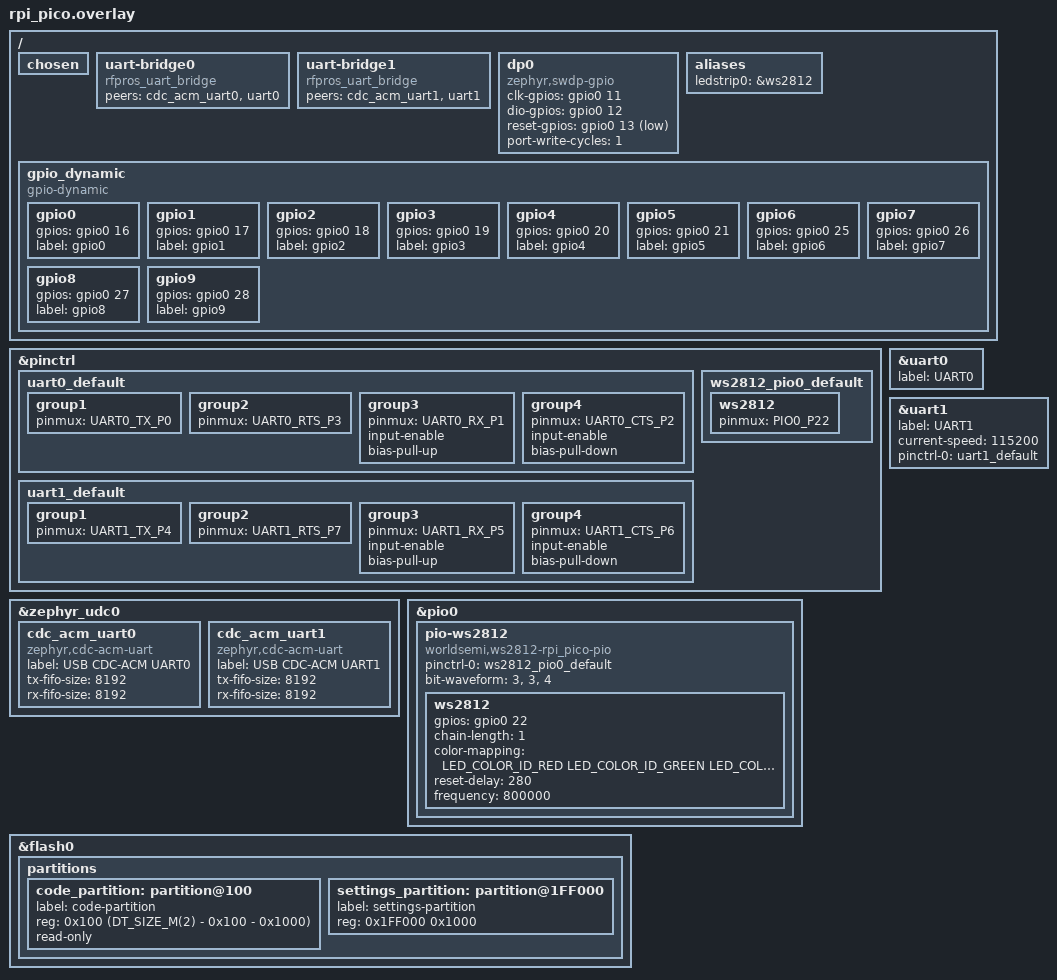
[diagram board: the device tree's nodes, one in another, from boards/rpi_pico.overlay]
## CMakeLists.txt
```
# SPDX-License-Identifier: LicenseRef-Ezurio-Clause

cmake_minimum_required(VERSION 3.20.0)

if(CONFIG_APP_DEBUG)
  set(EXTRA_CONF_FILE ${CMAKE_CURRENT_LIST_DIR}/debug.conf)
  set(EXTRA_DTC_OVERLAY_FILE ${CMAKE_CURRENT_LIST_DIR}/debug.overlay)
endif()

find_package(Zephyr REQUIRED HINTS)

project(dvk_probe)

zephyr_include_directories(include)
FILE(GLOB app_sources src/*.c)
target_sources(app PRIVATE ${app_sources})
```

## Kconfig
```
# Copyright 2025 Google LLC
# Copyright 2025 Ezurio
# SPDX-License-Identifier: LicenseRef-Ezurio-Clause

menu "DVK Probe options"
	depends on USB_DEVICE_STACK_NEXT
	depends on UART_INTERRUPT_DRIVEN
	depends on RING_BUFFER

module=DVK_PROBE
module-dep=LOG
module-str=Log level
source "${ZEPHYR_BASE}/subsys/logging/Kconfig.template.log_config"

config APP_USBD_MANUFACTURER
	string "USB device manufacturer string"
	default "Ezurio"
	help
	  USB device manufacturer string.

config APP_USBD_PRODUCT
	string "USB device product string"
	default "DVK Probe"
	help
	  USB device product string.

config APP_USBD_VID
	hex "USB device Vendor ID"
	default 0x3016
	help
	  USB device Vendor ID.

config APP_USBD_PID
	hex "USB device Product ID"
	default 0x0008
	help
	  USB device Product ID.

config APP_USBD_SELF_POWERED
	bool "USB device Self-powered attribute"
	help
	  Set the Self-powered attribute in the configuration.

config APP_USBD_REMOTE_WAKEUP
	bool "USB device Remote Wakeup attribute"
	help
	  Set the Remote Wakeup attribute in the configuration.

config APP_USBD_MAX_POWER
	int "USB device bMaxPower value"
	default 250
	range 0 250
	help
	  bMaxPower value in the configuration in 2 mA units.

config APP_USBD_20_EXTENSION_DESC
	bool "Use default USB 2.0 Extension Descriptor"
	default y
	depends on USBD_BOS_SUPPORT
	help
	  Set bcdUSB value to 0201 and use default USB 2.0 Extension Descriptor.

config APP_DEBUG
	bool "Enable debug logs"
	help
	  Enable debug logs for DVK Probe application.
	  This will add a USB CDC ACM port for debug logs.

config RFPROS_UART_BRIDGE_BUF_SIZE
	int "UART bridge buffer size"
	default 256
	help
	  Set the buffer size for the UART bridge.

endmenu

source "Kconfig.zephyr"
```

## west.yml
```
manifest:
  remotes:
    - name: zephyr
      url-base: https://github.com/zephyrproject-rtos/
    - name: rfpros
      url-base: https://github.com/rfpros

  defaults:
    remote: rfpros
    revision: main

  projects:
    - name: utp_python_common_lib
      revision: 3ceca9d6c383bc7f93e47808a18a3fa6aca86825
    - name: zephyr
      revision: 84c8e9c5e381e6b7518472a7183dcbc953458c22
      import:
        name-allowlist:
          - cmsis
          - cmsis_6
          - hal_rpi_pico
          - picolibc

  self:
    path: dvk_probe
```

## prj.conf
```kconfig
CONFIG_UART_CONSOLE=n

CONFIG_USB_DEVICE_STACK_NEXT=y
CONFIG_UDC_BUF_POOL_SIZE=16384
CONFIG_RFPROS_UART_BRIDGE_BUF_SIZE=8192

# Enable dedicated CDC ACM workqueue for better responsiveness
CONFIG_USBD_MAX_UDC_MSG=32
CONFIG_USBD_MSG_DEFERRED_MODE=n
CONFIG_USBD_CDC_ACM_WORKQUEUE=y
CONFIG_USBD_CDC_ACM_STACK_SIZE=2048

CONFIG_SERIAL=y
CONFIG_UART_LINE_CTRL=y
CONFIG_UART_USE_RUNTIME_CONFIGURE=y
CONFIG_USBD_CDC_ACM_CLASS=y
CONFIG_CDC_ACM_SERIAL_INITIALIZE_AT_BOOT=n

CONFIG_DAP=y
CONFIG_DAP_BACKEND_USB=y
CONFIG_DAP_BACKEND_USB_MAX_PACKET_SIZE=512
CONFIG_GPIO=y
CONFIG_CMSIS_DAP_PROBE_VENDOR="Ezurio"
CONFIG_CMSIS_DAP_PROBE_NAME="DVK Probe CMSIS-DAP"
CONFIG_CMSIS_DAP_BOARD_VENDOR="Ezurio"
CONFIG_CMSIS_DAP_BOARD_NAME="DVK"
CONFIG_CMSIS_DAP_DEVICE_VENDOR="Arm"
CONFIG_CMSIS_DAP_DEVICE_NAME="cortex_m"

CONFIG_LED_STRIP=y
CONFIG_WS2812_STRIP_RPI_PICO_PIO=y
CONFIG_ZBUS=y

# Flash and storage support
CONFIG_FLASH=y
CONFIG_FLASH_MAP=y
CONFIG_FLASH_PAGE_LAYOUT=y

# Reboot support
CONFIG_REBOOT=y
```

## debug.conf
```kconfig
CONFIG_LOG=y
CONFIG_UART_CONSOLE=y
CONFIG_LOG_BUFFER_SIZE=10240
CONFIG_LOG_PROCESS_THREAD_STARTUP_DELAY_MS=5000
CONFIG_LOG_PROCESS_THREAD_SLEEP_MS=15

CONFIG_SHELL=y

CONFIG_USBD_CDC_ACM_LOG_LEVEL_OFF=y
# CONFIG_UART_LOG_LEVEL_DBG=y
CONFIG_DAP_LOG_LEVEL_INF=y
CONFIG_USBD_LOG_LEVEL_WRN=y
CONFIG_DP_DRIVER_LOG_LEVEL_INF=y
```

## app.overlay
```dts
/*
 * Copyright 2025 Google LLC
 *
 * SPDX-License-Identifier: Apache-2.0
 */

/ {
	uart-bridge0 {
		compatible = "zephyr,uart-bridge";
		peers = <&cdc_acm_uart0 &uart0>;
	};
};

&zephyr_udc0 {
	cdc_acm_uart0: cdc_acm_uart0 {
		compatible = "zephyr,cdc-acm-uart";
		label = "Zephyr USB CDC-ACM";
	};
};
```

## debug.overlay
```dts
/ {
	chosen {
		// For debug console over USB CDC-ACM
		zephyr,console = &cdc_acm_uart2;
		zephyr,shell-uart = &cdc_acm_uart2;
	};
};

&zephyr_udc0 {
	cdc_acm_uart2: cdc_acm_uart2 {
		compatible = "zephyr,cdc-acm-uart";
		label = "DVK Probe DEBUG";
	};
};
```

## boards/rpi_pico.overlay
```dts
#include <dt-bindings/led/led.h>

/ {
	chosen {
		/delete-property/ zephyr,console;
		/delete-property/ zephyr,shell-uart;
	};

	uart-bridge0 {
		compatible = "rfpros_uart_bridge";
		peers = <&cdc_acm_uart0 &uart0>;
	};

	uart-bridge1 {
		compatible = "rfpros_uart_bridge";
		peers = <&cdc_acm_uart1 &uart1>;
	};

	dp0 {
		compatible = "zephyr,swdp-gpio";
		status = "okay";
		clk-gpios = <&gpio0 11 GPIO_ACTIVE_HIGH>;
		dio-gpios = <&gpio0 12 GPIO_PULL_UP>;
		reset-gpios = <&gpio0 13 (GPIO_ACTIVE_LOW | GPIO_PULL_UP)>;
		port-write-cycles = <1>;
	};

	aliases {
		ledstrip0 = &ws2812;
	};

	gpio_dynamic {
		compatible = "gpio-dynamic";
		gpio0 {
		   gpios = <&gpio0 16 0>;
		   label = "gpio0";
		};
		gpio1 {
		   gpios = <&gpio0 17 0>;
		   label = "gpio1";
		};
		gpio2 {
		   gpios = <&gpio0 18 0>;
		   label = "gpio2";
		};
		gpio3 {
		   gpios = <&gpio0 19 0>;
		   label = "gpio3";
		};
		gpio4 {
		   gpios = <&gpio0 20 0>;
		   label = "gpio4";
		};
		gpio5 {
		   gpios = <&gpio0 21 0>;
		   label = "gpio5";
		};
		gpio6 {
		   gpios = <&gpio0 25 0>;
		   label = "gpio6";
		};
		gpio7 {
		   gpios = <&gpio0 26 0>;
		   label = "gpio7";
		};
		gpio8 {
		   gpios = <&gpio0 27 0>;
		   label = "gpio8";
		};
		gpio9 {
		   gpios = <&gpio0 28 0>;
		   label = "gpio9";
		};
	 };
};

&pinctrl {
	uart0_default: uart0_default {
		group1 {
			pinmux = <UART0_TX_P0>;
		};
		group2 {
			pinmux = <UART0_RTS_P3>;
		};
		group3 {
			pinmux = <UART0_RX_P1>;
			input-enable;
			bias-pull-up;
		};
		group4 {
			pinmux = <UART0_CTS_P2>;
			input-enable;
			bias-pull-down;
		};
	};

	uart1_default: uart1_default {
		group1 {
			pinmux = <UART1_TX_P4>;
		};
		group2 {
			pinmux = <UART1_RTS_P7>;
		};
		group3 {
			pinmux = <UART1_RX_P5>;
			input-enable;
			bias-pull-up;
		};
		group4 {
			pinmux = <UART1_CTS_P6>;
			input-enable;
			bias-pull-down;
		};
	};

	ws2812_pio0_default: ws2812_pio0_default {
		ws2812 {
			pinmux = <PIO0_P22>;
		};
	};
};

&uart0 {
	label = "UART0";
};

&uart1 {
	label = "UART1";
	current-speed = <115200>;
	status = "okay";
	pinctrl-0 = <&uart1_default>;
	pinctrl-names = "default";
};

&zephyr_udc0 {
	cdc_acm_uart0: cdc_acm_uart0 {
		compatible = "zephyr,cdc-acm-uart";
		label = "USB CDC-ACM UART0";
		tx-fifo-size = <8192>;
		rx-fifo-size = <8192>;
	};

	cdc_acm_uart1: cdc_acm_uart1 {
		compatible = "zephyr,cdc-acm-uart";
		label = "USB CDC-ACM UART1";
		tx-fifo-size = <8192>;
		rx-fifo-size = <8192>;
	};
};

&pio0 {
	status = "okay";

	pio-ws2812 {
		compatible = "worldsemi,ws2812-rpi_pico-pio";
		status = "okay";
		pinctrl-0 = <&ws2812_pio0_default>;
		pinctrl-names = "default";
		bit-waveform = <3>, <3>, <4>;

		ws2812: ws2812 {
			status = "okay";
			gpios = <&gpio0 22 GPIO_ACTIVE_HIGH>;
			chain-length = <1>;
			color-mapping = <LED_COLOR_ID_RED
				LED_COLOR_ID_GREEN
				LED_COLOR_ID_BLUE>;
			reset-delay = <280>;
			frequency = <800000>;
		};
	};
};

&flash0 {
	partitions {
		/*
		 * Usable flash. Starts at 0x100, after the bootloader. The partition
		 * size is 2MB minus the 0x100 bytes taken by the bootloader and the settings area.
		 */
		code_partition: partition@100 {
			label = "code-partition";
			reg = <0x100 (DT_SIZE_M(2) - 0x100 - 0x1000)>;
			read-only;
		};

		settings_partition: partition@1FF000 {
			label = "settings-partition";
			reg = <0x1FF000 0x1000>;
		};
	};
};
```

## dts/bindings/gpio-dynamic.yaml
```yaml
# Copyright (c) 2018, Linaro Limited
# Copyright (c) 2023-2024, Laird Connectivity
#
# SPDX-License-Identifier: Apache-2.0

description: |
  This allows you to define a group of GPIO that are configurable at run-time.
  Each pin is defined in a child node of the gpio-dynamic node.

  This example defines three children in the node /gpio_dynamic.

  The GPIO flags are ignored by the pi_dapi_gpio driver because they are
  set from the [Python] application.

  / {
     gpio_dynamic {
        compatible = "gpio-dynamic";
        test_point_0 {
           gpios = <&gpio0 1 0>;
           label = "TEST_POINT_0,TP0";
        };
        test_point_1 {
           gpios = <&gpio0 2 0>;
           label = "TEST_POINT_1";
        };
        test_point_2 {
           gpios = <&gpio1 15 0>;
        };
     };
  };

compatible: "gpio-dynamic"

child-binding:
    description: Dynamic GPIO child node
    properties:
       gpios:
          type: phandle-array
          required: true
       label:
          type: string
          description: |
            Human readable string describing the gpio. It can be used by an
            application/script to identify this test point or to retrieve 
            its number/index (i.e. child node number) on the parent device.
            Multiple names can be specified as a comma separated list.
```

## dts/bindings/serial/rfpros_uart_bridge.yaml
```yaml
# Copyright 2025 Google LLC
# Copyright 2025 Ezurio
# SPDX-License-Identifier: LicenseRef-Ezurio-Clause

title: UART bridge

description: |
  Bridges data between two serial devices, for example a USB CDC-ACM serial
  port and an hardware UART.

  The device node must specify exactly two peer phandles for the two serial
  devices to be bridged together. Example configuration:

  uart-bridge {
           compatible = "rfpros_uart_bridge";
           peers = <&cdc_acm_uart0 &uart1>;
  };

include: base.yaml

compatible: "rfpros_uart_bridge"

properties:
  peers:
    type: phandles
    description: Peer device nodes, must contain two phandles
```

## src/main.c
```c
/*
 * Copyright 2025 Google LLC
 * Copyright 2025 Ezurio
 *
 * SPDX-License-Identifier: LicenseRef-Ezurio-Clause
 */

#include <stdio.h>
#include <string.h>
#include <zephyr/kernel.h>
#include <zephyr/drivers/gpio.h>
#include <zephyr/drivers/uart.h>
#include <zephyr/usb/usb_device.h>
#include <zephyr/usb/usbd.h>
#include <zephyr/app_version.h>
#include <cmsis_dap.h>

#include <zephyr/logging/log.h>
LOG_MODULE_REGISTER(dvk_probe, CONFIG_DVK_PROBE_LOG_LEVEL);

#include "uart_bridge.h"
#include "app_usbd.h"
#include "led.h"
#include "probe_settings.h"
#include "dap_vendor.h"

#define TARGET_RESET_PULSE_MS 50

static struct usbd_context *app_usbd;

#define DEVICE_DT_GET_COMMA(node_id) DEVICE_DT_GET(node_id),

static const struct device *const swd_dev = DEVICE_DT_GET_ONE(zephyr_swdp_gpio);

static const struct device *uart_bridges[] = {
	DT_FOREACH_STATUS_OKAY(rfpros_uart_bridge, DEVICE_DT_GET_COMMA)};

/* Get the node ID of gpio_dynamic */
#define GPIO_DYNAMIC_NODE DT_PATH(gpio_dynamic)

/* Macro to extract gpio_dt_spec from a child node */
#define GPIO_SPEC_FROM_CHILD(child_node) GPIO_DT_SPEC_GET_BY_IDX(child_node, gpios, 0),

/* Get all dynamic GPIOs */
static const struct gpio_dt_spec gpios[] = {
	DT_FOREACH_CHILD(GPIO_DYNAMIC_NODE, GPIO_SPEC_FROM_CHILD)};

/* Target reset GPIO */
#define SWDP_NODE DT_COMPAT_GET_ANY_STATUS_OKAY(zephyr_swdp_gpio)
static const struct gpio_dt_spec target_reset_gpio =
	GPIO_DT_SPEC_GET(SWDP_NODE, reset_gpios);

ZBUS_CHAN_DECLARE(led_chan);
ZBUS_SUBSCRIBER_DEFINE(led_sub, 8);

static void usbd_msg_cb(struct usbd_context *const ctx, const struct usbd_msg *msg)
{
	uint32_t line_ctrl_status;
	uint8_t dev_idx;
	const struct device *uart_dev = NULL;
	int ret;
	struct uart_config peer_cfg;

	LOG_DBG("USBD message: %s", usbd_msg_type_string(msg->type));

	if (usbd_can_detect_vbus(ctx)) {
		if (msg->type == USBD_MSG_VBUS_READY) {
			if (usbd_enable(ctx)) {
				LOG_ERR("Failed to enable device support");
			}
		}

		if (msg->type == USBD_MSG_VBUS_REMOVED) {
			if (usbd_disable(ctx)) {
				LOG_ERR("Failed to disable device support");
			}
		}
	}

	if (msg->type == USBD_MSG_CDC_ACM_LINE_CODING ||
	    msg->type == USBD_MSG_CDC_ACM_CONTROL_LINE_STATE) {
		for (dev_idx = 0; dev_idx < ARRAY_SIZE(uart_bridges); dev_idx++) {
			/* Find the matching device */
			uart_dev = uart_bridge_get_peer(msg->dev, uart_bridges[dev_idx]);
			if (uart_dev != NULL) {
				break;
			}
		}

		if (uart_dev == NULL) {
			LOG_DBG("No matching UART bridge for %s", msg->dev->name);
			return;
		}

		/* Get the current UART configuration of the USB CDC ACM device */
		ret = uart_config_get(msg->dev, &peer_cfg);
		if (ret != 0) {
			LOG_ERR("Failed to get UART config: %d", ret);
			return;
		}

		/* Check if the USB CDC ACM device is ready for operation */
		ret = uart_line_ctrl_get(msg->dev, UART_LINE_CTRL_DTR, &line_ctrl_status);
		if (ret == 0) {
			if (line_ctrl_status) {
				LOG_INF("DTR set: enable UART bridge %s", uart_dev->name);
				uart_bridge_settings_update(msg->dev, uart_bridges[dev_idx]);
				peer_cfg.flow_ctrl = UART_CFG_FLOW_CTRL_RTS_CTS;
			} else {
				LOG_INF("DTR cleared: disable UART bridge %s", uart_dev->name);
				/* This sets RTS back high when the USB UART is closed */
				peer_cfg.flow_ctrl = UART_CFG_FLOW_CTRL_NONE;
			}

			ret = uart_configure(uart_dev, &peer_cfg);
			if (ret) {
				LOG_ERR("%s: failed to set the uart config: %d", uart_dev->name,
					ret);
				return;
			}
		} else {
			LOG_ERR("Failed to get DTR status: %d", ret);
		}
	}
}

int main(void)
{
	int err;
	led_action_t led_boot_action = {
		.dev = led_strip,
		.color = LED_COLOR_WHITE,
		.on_time_ms = LED_FLASH_TIME_MS,
		.off_time_ms = LED_FLASH_TIME_MS,
		.repeat_count = 2,
	};
	led_action_t msg_led_action;
	const struct zbus_channel *chan;

	for (size_t i = 0; i < ARRAY_SIZE(gpios); i++) {
		if (gpio_pin_configure_dt(&gpios[i], GPIO_DISCONNECTED) != 0) {
			LOG_ERR("Could not configure GPIO %s", gpios[i].port->name);
		}
	}

	if (led_init() != 0) {
		LOG_ERR("LED strip device %s is not ready", led_strip->name);
		return -ENODEV;
	}

	err = dap_setup(swd_dev);
	if (err) {
		LOG_ERR("Failed to initialize DAP controller, %d", err);
		return err;
	}

	dap_set_fw_version(APP_VERSION_STRING);

	err = dap_set_vendor_cmd_callback(dap_vendor_cmd_handler);
	if (err < 0) {
		LOG_ERR("Failed to register vendor command callback: %d", err);
	}

	/* Initialize probe settings */
	probe_settings_init();

	/* Set DAP device info from probe settings */
	if (probe_settings != NULL && probe_settings->base.version >= PROBE_SETTINGS_V1) {
		err = dap_set_device_info(probe_settings->v1.target_device_vendor,
					  probe_settings->v1.target_device_name,
					  probe_settings->v1.target_board_vendor,
					  probe_settings->v1.target_board_name);
		if (err) {
			LOG_WRN("Failed to set DAP device info: %d", err);
		} else {
			LOG_INF("DAP device info set from probe settings");
		}
	}

	app_usbd = app_usbd_setup_device(usbd_msg_cb);
	if (app_usbd == NULL) {
		LOG_ERR("Failed to setup USB device");
		return -ENODEV;
	}

	/* Set USB VID and PID from probe settings */
	if (probe_settings != NULL && probe_settings->base.version >= PROBE_SETTINGS_V2) {
		err = usbd_device_set_vid(app_usbd, probe_settings->v2.usb_vid);
		if (err) {
			LOG_WRN("Failed to set USB VID: %d", err);
		}
		err = usbd_device_set_pid(app_usbd, probe_settings->v2.usb_pid);
		if (err) {
			LOG_WRN("Failed to set USB PID: %d", err);
		}
		LOG_INF("USB VID:PID set to 0x%04x:0x%04x", probe_settings->v2.usb_vid,
			probe_settings->v2.usb_pid);
	}

	/* Reset target device on boot */
	if (!gpio_is_ready_dt(&target_reset_gpio)) {
		LOG_ERR("Target reset GPIO is not ready");
	} else {
		err = gpio_pin_configure_dt(&target_reset_gpio, GPIO_OUTPUT_ACTIVE);
		if (err) {
			LOG_ERR("Failed to configure target reset GPIO: %d", err);
		} else {
			LOG_DBG("Asserting target reset");
			k_msleep(TARGET_RESET_PULSE_MS);
			gpio_pin_set_dt(&target_reset_gpio, 0);
			LOG_DBG("Released target reset");
			/* Set back to disconnected so DAP can control it */
			gpio_pin_configure_dt(&target_reset_gpio, GPIO_DISCONNECTED);
		}
	}

	/* Initialize USB device */
	err = usbd_init(app_usbd);
	if (err) {
		LOG_ERR("Failed to initialize USB device: %d", err);
		return err;
	}

	if (!usbd_can_detect_vbus(app_usbd)) {
		err = usbd_enable(app_usbd);
		if (err) {
			LOG_ERR("Failed to enable device support");
			return err;
		}
	}

	LOG_INF("USB device support enabled");

	/* Flash LED to indicate boot */
	led_send_action(&led_boot_action);

	/* Main loop to process LED actions */
	while (1) {
		err = zbus_sub_wait(&led_sub, &chan, K_FOREVER);
		if (err) {
			LOG_ERR("Failed to wait for LED action: %d", err);
			k_yield();
			continue;
		}
		if (chan != &led_chan) {
			k_yield();
			continue;
		}
		err = zbus_chan_read(&led_chan, &msg_led_action, K_FOREVER);
		if (err == 0) {
			led_do_action(&msg_led_action);
		}
		k_sleep(K_MSEC(1));
		k_yield();
	}
	return 0;
}
```

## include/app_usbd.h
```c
/*
 * Copyright (c) 2023 Nordic Semiconductor ASA.
 * Copyright 2025 Ezurio
 *
 * SPDX-License-Identifier: LicenseRef-Ezurio-Clause
 */

#ifndef APP_USBD_H
#define APP_USBD_H

#include <stdint.h>
#include <zephyr/usb/usbd.h>

/*
 * This function configures and initializes a
 * USB device. It configures the device context, default string descriptors,
 * USB device configuration, registers any available class instances, and
 * finally initializes USB device.
 *
 * It returns the configured and initialized USB device context on success,
 * otherwise it returns NULL.
 */
struct usbd_context *app_usbd_init_device(usbd_msg_cb_t msg_cb);

/*
 * This function is similar to app_usbd_init_device(), but does not
 * initialize the device. It allows the application to set additional features,
 * such as additional descriptors.
 */
struct usbd_context *app_usbd_setup_device(usbd_msg_cb_t msg_cb);

#endif /* APP_USBD_H */
```

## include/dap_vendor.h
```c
/**
 * @file dap_vendor.h
 *
 * Copyright (c) 2026 Ezurio
 *
 * SPDX-License-Identifier: LicenseRef-Ezurio-Clause
 */

#ifndef __DAP_VENDOR_H__
#define __DAP_VENDOR_H__

/**************************************************************************************************/
/* Includes                                                                                       */
/**************************************************************************************************/
#include <cmsis_dap.h>

#ifdef __cplusplus
extern "C" {
#endif

/**************************************************************************************************/
/* Global Constants, Macros and Type Definitions                                                  */
/**************************************************************************************************/

/* clang-format off */
/**
 * @brief Set IO to input or output
 * @param uint8_t gpio to set
 * @param uint8_t direction 1 = output, 0 = input
 * @param uint8_t option 0 = no-pull, 1 = pull-up, 2 = pull-down, 3 = disconnect
 */
#define ID_DAP_VENDOR_SET_IO_DIR        ID_DAP_VENDOR31
/**
 * @brief Set IO to high or low
 * @param uint8_t gpio to set
 * @param uint8_t level 1 = high, 0 = low
 */
#define ID_DAP_VENDOR_SET_IO            (ID_DAP_VENDOR31 - 1)
/**
 * @brief Read IO state
 * @param uint8_t gpio to read
 * @return uint8_t < 0 error, 1 = high, 0 = low
 */
#define ID_DAP_VENDOR_READ_IO           (ID_DAP_VENDOR31 - 2)

/**
 * @brief Deprecated EEPROM read/write functions. Use read/write settings instead.
 * These defines are here for informational purposes only.
 */
#define ID_DAP_VENDOR_READ_BOARD_ID_BYTES   (ID_DAP_VENDOR31 - 3)
#define ID_DAP_VENDOR_WRITE_BOARD_ID_BYTES  (ID_DAP_VENDOR31 - 4)

/**
 * @brief Reboot the debug probe
 * @param uint8_t reboot to bootloader if 1, else reboot and run application
 */
#define ID_DAP_VENDOR_REBOOT                (ID_DAP_VENDOR31 - 5)

/**
 * @brief Read settings from probe (internal flash)
 * @return bytes read. length of bytes read is always 256 bytes. < 0 indicates error
 */
#define ID_DAP_VENDOR_READ_SETTINGS         (ID_DAP_VENDOR31 - 6)

/**
 * @brief Write settings to probe (internal flash)
 * @param uint8_t number of bytes to write (max 256)
 * @param uint8_t* bytes to write. This will always be 256 bytes (a full settings page)
 * @return int8_t result 0 on success, < 0 indicates error
 */
#define ID_DAP_VENDOR_WRITE_SETTINGS        (ID_DAP_VENDOR31 - 7)

/* clang-format on */

enum {
	DAP_VENDOR_ERR_INVALID_IO = 1,
	DAP_VENDOR_ERR_INVALID_IO_OPTION,
	DAP_VENDOR_ERR_INVALID_SIZE,
};

enum {
	IO_OPTION_NO_PULL = 0,
	IO_OPTION_PULL_UP,
	IO_OPTION_PULL_DOWN,
	IO_OPTION_DISCONNECT,
	IO_OPTION_INVALID,
};

/**************************************************************************************************/
/* Global Function Prototypes                                                                     */
/**************************************************************************************************/
uint16_t dap_vendor_cmd_handler(uint8_t cmd_id,
				      const uint8_t *request,
				      uint8_t *response);

#ifdef __cplusplus
}
#endif

#endif /* __DAP_VENDOR_H__ */
```

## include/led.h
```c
/*
 * Copyright 2025 Ezurio
 *
 * SPDX-License-Identifier: LicenseRef-Ezurio-Clause
 */

#ifndef APP_LED_H
#define APP_LED_H

#include <zephyr/device.h>
#include <zephyr/drivers/led_strip.h>
#include <zephyr/zbus/zbus.h>

#if DT_NODE_HAS_PROP(DT_ALIAS(ledstrip0), chain_length)
#define LED_STRIP_NUM_PIXELS DT_PROP(DT_ALIAS(ledstrip0), chain_length)
#else
#error Unable to determine length of LED strip
#endif

#define LED_LEVEL_LIMIT 0.25 /* Limit max brightness to 25% to protect eyes */

#define LED_RGB(_r, _g, _b)                                                                        \
	{.r = ((uint8_t)((_r) * LED_LEVEL_LIMIT)),                                                 \
	 .g = ((uint8_t)((_g) * LED_LEVEL_LIMIT)),                                                 \
	 .b = ((uint8_t)((_b) * LED_LEVEL_LIMIT))}

#define LED_COLOR_RED   LED_RGB(255, 0, 0)
#define LED_COLOR_GREEN LED_RGB(0, 255, 0)
#define LED_COLOR_BLUE  LED_RGB(0, 0, 255)
#define LED_COLOR_WHITE  LED_RGB(255, 255, 255)
#define LED_COLOR_OFF   LED_RGB(0, 0, 0)

#define LED_FLASH_TIME_MS      30
#define LED_FLASH_FAST_TIME_MS 10

typedef struct led_action {
	const struct device *dev;
	struct led_rgb color;
	uint16_t on_time_ms;
	uint16_t off_time_ms;
	uint16_t repeat_count;
} led_action_t;

typedef enum {
	LED_BLACK, /* OFF */
	LED_RED,
	LED_GREEN,
	LED_BLUE,
	LED_WHITE,
	NUMBER_OF_LED_COLORS,
} led_color_t;

extern const struct device *const led_strip;
extern const led_action_t LED_BLUE_FLASH;
extern const led_action_t LED_RED_FLASH;
extern const led_action_t LED_GREEN_FLASH;

/**
 * @brief Send LED action to LED handler
 *
 * @param action An action to be performed on the LED. This queues the action for processing.
 *		The LED action is designed to flash LEDs and is not suitable for setting steady
 *		states.
 * @return int 0 on success, negative error code on failure
 */
int led_send_action(led_action_t *action);

/**
 * @brief Perform LED action
 *
 * @param action An action to be performed on the LED.
 *		This is a blocking call. It cannot be called from an interrupt context.
 *		The LED action is designed to flash LEDs and is not suitable for setting steady
 *		states.
 * @return int 0 on success, negative error code on failure
 */
int led_do_action(led_action_t *action);

/**
 * @brief Toggle LED color channels
 *
 * @param led_color Color channel to toggle.
 */
void toggle_led(led_color_t led_color);

/**
 * @brief Turn off specified LED color channel
 *
 * @param led_color Color channel to turn off.
 */
void led_off(led_color_t led_color);

/**
 * @brief Initialize LED subsystem
 */
int led_init(void);

#endif /* APP_LED_H */
```

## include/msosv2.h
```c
/*
 * Copyright (c) 2016-2019 Intel Corporation
 * Copyright (c) 2023-2024 Nordic Semiconductor ASA
 * Copyright 2025 Ezurio
 *
 * SPDX-License-Identifier: LicenseRef-Ezurio-Clause
 */

#ifndef APP_MSOSV2_DESCRIPTOR_H
#define APP_MSOSV2_DESCRIPTOR_H

/*
 * Microsoft OS 2.0 Descriptors for Windows 8.1+ compatibility.
 * See Microsoft OS 2.0 Descriptors Specification for reference.
 */

#define APP_MSOS_VENDOR_CODE 0x14U
/* Windows version (8.1) */
#define APP_MSOS2_OS_VERSION 0x06030000UL

/* {F9E8D7C6-B5A4-3210-DCBA-0987654321FE} */
#define CMSIS_DAP_V2_DEVICE_INTERFACE_GUID                                                         \
	'{', 0x00, 'F', 0x00, '9', 0x00, 'E', 0x00, '8', 0x00, 'D', 0x00, '7', 0x00, 'C', 0x00,    \
		'6', 0x00, '-', 0x00, 'B', 0x00, '5', 0x00, 'A', 0x00, '4', 0x00, '-', 0x00, '3',  \
		0x00, '2', 0x00, '1', 0x00, '0', 0x00, '-', 0x00, 'D', 0x00, 'C', 0x00, 'B', 0x00, \
		'A', 0x00, '-', 0x00, '0', 0x00, '9', 0x00, '8', 0x00, '7', 0x00, '6', 0x00, '5',  \
		0x00, '4', 0x00, '3', 0x00, '2', 0x00, '1', 0x00, 'F', 0x00, 'E', 0x00, '}', 0x00, \
		0x00, 0x00, 0x00, 0x00

/* CMSIS-DAP is always registered first, so it is always interface 0. */
#define DAP_INTERFACE_NUMBER   0

/*
 * The DAP function subset contains the WinUSB compatible ID and device interface GUID.
 */
#define DAP_FUNCTION_SUBSET_LENGTH                                                                 \
	(sizeof(struct msosv2_function_subset_header) + sizeof(struct msosv2_compatible_id) +      \
	 sizeof(struct msosv2_guids_property))

/*
 * Microsoft OS 2.0 Descriptor Set
 */
struct msosv2_descriptor {
	struct msosv2_descriptor_set_header header;
	/* DAP interface function subset header */
	struct msosv2_function_subset_header dap_subset_header;
	struct msosv2_compatible_id compatible_id;
	struct msosv2_guids_property guids_property;
} __packed;

const struct msosv2_descriptor msosv2_desc = {
	.header =
		{
			.wLength = sizeof(struct msosv2_descriptor_set_header),
			.wDescriptorType = MS_OS_20_SET_HEADER_DESCRIPTOR,
			.dwWindowsVersion = sys_cpu_to_le32(APP_MSOS2_OS_VERSION),
			.wTotalLength = sizeof(msosv2_desc),
		},
	/* DAP is always interface 0 */
	.dap_subset_header =
		{
			.wLength = sizeof(struct msosv2_function_subset_header),
			.wDescriptorType = MS_OS_20_SUBSET_HEADER_FUNCTION,
			.bFirstInterface = DAP_INTERFACE_NUMBER,
			.bReserved = 0,
			.wSubsetLength = DAP_FUNCTION_SUBSET_LENGTH,
		},
	.compatible_id =
		{
			.wLength = sizeof(struct msosv2_compatible_id),
			.wDescriptorType = MS_OS_20_FEATURE_COMPATIBLE_ID,
			.CompatibleID = {'W', 'I', 'N', 'U', 'S', 'B', 0x00, 0x00},
		},
	.guids_property =
		{
			.wLength = sizeof(struct msosv2_guids_property),
			.wDescriptorType = MS_OS_20_FEATURE_REG_PROPERTY,
			.wPropertyDataType = MS_OS_20_PROPERTY_DATA_REG_MULTI_SZ,
			.wPropertyNameLength = 42,
			.PropertyName = {DEVICE_INTERFACE_GUIDS_PROPERTY_NAME},
			.wPropertyDataLength = 80,
			.bPropertyData = {CMSIS_DAP_V2_DEVICE_INTERFACE_GUID},
		},
};

/*
 * Microsoft OS 2.0 Platform Capability Descriptor
 * Combined structure using Zephyr's standard BOS types
 */
struct bos_msosv2_descriptor {
	struct usb_bos_platform_descriptor platform;
	struct usb_bos_capability_msos msos;
} __packed;

const struct bos_msosv2_descriptor bos_msosv2_desc = {
	.platform =
		{
			.bLength = sizeof(struct usb_bos_platform_descriptor) +
				   sizeof(struct usb_bos_capability_msos),
			.bDescriptorType = USB_DESC_DEVICE_CAPABILITY,
			.bDevCapabilityType = USB_BOS_CAPABILITY_PLATFORM,
			.bReserved = 0,
			/* Microsoft OS 2.0 descriptor platform capability UUID
			 * D8DD60DF-4589-4CC7-9CD2-659D9E648A9F
			 */
			.PlatformCapabilityUUID =
				{
					0xDF,
					0x60,
					0xDD,
					0xD8,
					0x89,
					0x45,
					0xC7,
					0x4C,
					0x9C,
					0xD2,
					0x65,
					0x9D,
					0x9E,
					0x64,
					0x8A,
					0x9F,
				},
		},
	.msos =
		{
			.dwWindowsVersion = sys_cpu_to_le32(APP_MSOS2_OS_VERSION),
			.wMSOSDescriptorSetTotalLength = sys_cpu_to_le16(sizeof(msosv2_desc)),
			.bMS_VendorCode = APP_MSOS_VENDOR_CODE,
			.bAltEnumCode = 0x00,
		},
};

static int msos_to_host_cb(const struct usbd_context *const ctx,
			   const struct usb_setup_packet *const setup, struct net_buf *const buf)
{
	uint16_t wIndex = sys_le16_to_cpu(setup->wIndex);

	LOG_INF("MSOS Vendor callback: bRequest=0x%02x, wIndex=0x%04x", setup->bRequest, wIndex);

	/* Handle MSOS v2 requests (Windows 8.1+) */
	if (setup->bRequest == APP_MSOS_VENDOR_CODE && wIndex == MS_OS_20_DESCRIPTOR_INDEX) {
		LOG_INF("Get MS OS 2.0 Descriptor Set (len=%u)", sizeof(msosv2_desc));
		net_buf_add_mem(buf, &msosv2_desc, MIN(net_buf_tailroom(buf), sizeof(msosv2_desc)));
		return 0;
	}

	LOG_WRN("Unsupported MSOS vendor request");
	return -ENOTSUP;
}

/* Register MSOS v2 BOS descriptor with vendor request callback */
USBD_DESC_BOS_VREQ_DEFINE(bos_vreq_msosv2, sizeof(bos_msosv2_desc), &bos_msosv2_desc,
			  APP_MSOS_VENDOR_CODE, msos_to_host_cb, NULL);

#endif /* APP_MSOSV2_DESCRIPTOR_H */
```

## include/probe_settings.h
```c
/**
 * @file probe_settings.h
 * @brief API for probe NV settings
 *
 * Copyright (c) 2026 Ezurio
 *
 * SPDX-License-Identifier: LicenseRef-Ezurio-Clause
 */

#ifndef __PROBE_SETTINGS_H__
#define __PROBE_SETTINGS_H__

#ifdef __cplusplus
extern "C" {
#endif

/**************************************************************************************************/
/* Global Constants, Macros and Type Definitions                                                  */
/**************************************************************************************************/
/* clang-format off */
#define PROBE_SETTINGS_MAX_SIZE 	256
#define PROBE_SETTINGS_INVALID_FF   0xFF
#define PROBE_SETTINGS_INVALID_00   0x00
#define PROBE_SETTINGS_V1       	0x01
#define PROBE_SETTINGS_V2      		0x02
/* clang-format on */

#pragma pack(1)
typedef struct {
	uint8_t version;
	uint8_t data[PROBE_SETTINGS_MAX_SIZE - 1];
} probe_settings_base_t;

typedef struct {
	uint8_t version;
	char target_device_vendor[32];
	char target_device_name[32];
	char target_board_vendor[32];
	char target_board_name[32];
} probe_settings_v1_t;

typedef struct {
	uint8_t version;
	char target_device_vendor[32];
	char target_device_name[32];
	char target_board_vendor[32];
	char target_board_name[32];
	uint16_t usb_vid;
	uint16_t usb_pid;
} probe_settings_v2_t;

typedef union {
	probe_settings_base_t base;
	probe_settings_v1_t v1;
	probe_settings_v2_t v2;
} probe_settings_ut;
#pragma pack()

enum {
	SETTINGS_ERR_INVALID_PARAM = 1,
};

/**************************************************************************************************/
/* Global Data Definitions                                                                        */
/**************************************************************************************************/
extern const probe_settings_ut *probe_settings;

/**************************************************************************************************/
/* Global Function Prototypes                                                                     */
/**************************************************************************************************/
void probe_settings_init(void);

/**
 * @brief Write settings to internal flash
 *
 * @param settings pointer to settings data
 * @param size size of settings data
 * @return int 0 on success, < 0 on failure
 */
int write_internal_settings(const probe_settings_ut *settings, uint16_t size);

#ifdef __cplusplus
}
#endif

#endif /* __PROBE_SETTINGS_H__ */
```

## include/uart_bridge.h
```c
/*
 * Copyright 2025 Google LLC
 * Copyright 2025 Ezurio
 *
 * SPDX-License-Identifier: LicenseRef-Ezurio-Clause
 */

#ifndef RFPROS_UART_BRIDGE_H
#define RFPROS_UART_BRIDGE_H

#include <zephyr/device.h>

/**
 * @brief Update the hardware port settings on a uart bridge
 *
 * If dev is part bridge_dev, then the dev uart configuration are applied to
 * the other device in the uart bridge. This allows propagating the settings
 * from a USB CDC-ACM port to a hardware UART.
 *
 * If dev is not part of bridge_dev then the function is a no-op.
 */
void uart_bridge_settings_update(const struct device *dev, const struct device *bridge_dev);

/**
 * @brief Get the peer device in a uart bridge
 *
 * @param dev The device to find the peer for
 * @param bridge_dev The uart bridge device
 * @return const struct device* The peer device, or NULL if not found
 */
const struct device *uart_bridge_get_peer(const struct device *dev,
					  const struct device *bridge_dev);

#endif /* RFPROS_UART_BRIDGE_H */
```

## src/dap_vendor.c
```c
/*
 * @file dap_vendor.c
 *
 * Copyright 2026 Ezurio
 * Copyright (c) 2023 Laird Connectivity LLC
 *
 * SPDX-License-Identifier: LicenseRef-Ezurio-Clause
 */

/**************************************************************************************************/
/* Includes                                                                                       */
/**************************************************************************************************/
#include <zephyr/kernel.h>
#include <zephyr/drivers/gpio.h>
#include <zephyr/sys/reboot.h>
#include <zephyr/logging/log.h>
#include <pico/bootrom.h>
#include <string.h>
#include "dap_vendor.h"
#include "probe_settings.h"
#include "led.h"

LOG_MODULE_REGISTER(dap_vendor, LOG_LEVEL_INF);

/**************************************************************************************************/
/* Local Constant, Macro and Type Definitions                                                     */
/**************************************************************************************************/
#define REBOOT_DELAY_MS 100

// Get the node ID of gpio_dynamic
#define GPIO_DYNAMIC_NODE DT_PATH(gpio_dynamic)

// Macro to extract gpio_dt_spec from a child node
#define GPIO_SPEC_FROM_CHILD(child_node) GPIO_DT_SPEC_GET_BY_IDX(child_node, gpios, 0),

/**************************************************************************************************/
/* Local Data Definitions                                                                         */
/**************************************************************************************************/
// Get all dynamic GPIOs
static const struct gpio_dt_spec gpios[] = {
	DT_FOREACH_CHILD(GPIO_DYNAMIC_NODE, GPIO_SPEC_FROM_CHILD)};

static struct k_work_delayable reboot_work;
static struct k_work_delayable reboot_bootloader_work;

/**************************************************************************************************/
/* Local Function Definitions                                                                     */
/**************************************************************************************************/
static void reboot_work_handler(struct k_work *work)
{
	/* Reboot the system */
	sys_reboot(SYS_REBOOT_COLD);
}

static void reboot_bootloader_work_handler(struct k_work *work)
{
	ARG_UNUSED(work);

	/* Reboot to the bootloader. This call never returns. */
	reset_usb_boot(0, 0);
}

static int convert_io(uint8_t io)
{
	switch (io) {
	case 16:
		return 0;
	case 17:
		return 1;
	case 18:
		return 2;
	case 19:
		return 3;
	case 20:
		return 4;
	case 21:
		return 5;
	case 25:
		return 6;
	case 26:
		return 7;
	case 27:
		return 8;
	case 28:
		return 9;
	default:
		return -1;
	}
}

static int check_io_range(uint8_t io)
{
	int gpio = convert_io(io);
	if (gpio < 0) {
		return -DAP_VENDOR_ERR_INVALID_IO;
	}

	return 0;
}

static int set_io_dir(uint8_t gpio, uint8_t dir, uint8_t option)
{
	int ret = 0;
	gpio_flags_t flags = 0;
	uint8_t io;

	ret = check_io_range(gpio);
	if (ret != 0) {
		return ret;
	}

	io = convert_io(gpio);

	if (option >= IO_OPTION_INVALID) {
		ret = -DAP_VENDOR_ERR_INVALID_IO_OPTION;
		return ret;
	}

	if (option == IO_OPTION_DISCONNECT) {
		/* Disconnect the pin */
		ret = gpio_pin_configure_dt(&gpios[io], GPIO_DISCONNECTED);
		return ret;
	}

	/* Set direction: input or output */
	if (dir) {
		flags = GPIO_OUTPUT;
	} else {
		flags = GPIO_INPUT;

		/* Configure pull resistors for inputs */
		if (option == IO_OPTION_PULL_DOWN) {
			flags |= GPIO_PULL_DOWN;
		} else if (option == IO_OPTION_PULL_UP) {
			flags |= GPIO_PULL_UP;
		}
	}

	ret = gpio_pin_configure_dt(&gpios[io], flags);
	return ret;
}

static int set_io(uint8_t gpio, uint8_t level)
{
	int ret = 0;
	uint8_t io;

	ret = check_io_range(gpio);
	if (ret != 0) {
		return ret;
	}

	io = convert_io(gpio);

	ret = gpio_pin_set_raw(gpios[io].port, gpios[io].pin, level);
	return ret;
}

static int read_io(uint8_t gpio)
{
	int ret = 0;
	uint8_t io;

	ret = check_io_range(gpio);
	if (ret != 0) {
		return ret;
	}

	io = convert_io(gpio);

	ret = gpio_pin_get_raw(gpios[io].port, gpios[io].pin);
	return ret;
}

/**************************************************************************************************/
/* Global Function Definitions                                                                    */
/**************************************************************************************************/
uint16_t dap_vendor_cmd_handler(uint8_t cmd_id, const uint8_t *request, uint8_t *response)
{
	int ret;
	int temp;
	uint16_t response_len = 2;
	bool flash_led = true;

	/* First byte is always the command ID */
	response[0] = cmd_id;

	switch (cmd_id) {
	case ID_DAP_VENDOR_SET_IO_DIR:
		ret = set_io_dir(request[0], request[1], request[2]);
		response[1] = ret;
		break;

	case ID_DAP_VENDOR_SET_IO:
		ret = set_io(request[0], request[1]);
		response[1] = ret;
		break;

	case ID_DAP_VENDOR_READ_IO:
		ret = read_io(request[0]);
		response[1] = ret;
		break;

	case ID_DAP_VENDOR_REBOOT:
		if (request[0]) {
			k_work_init_delayable(&reboot_bootloader_work,
					      reboot_bootloader_work_handler);
			k_work_schedule(&reboot_bootloader_work, K_MSEC(REBOOT_DELAY_MS));
			response[1] = 0;
		} else {
			/* Schedule a delayed reboot so the USB response can be sent */
			k_work_init_delayable(&reboot_work, reboot_work_handler);
			k_work_schedule(&reboot_work, K_MSEC(REBOOT_DELAY_MS));
			response[1] = 0;
		}
		break;

	case ID_DAP_VENDOR_READ_SETTINGS:
		if (probe_settings != NULL) {
			memcpy(&response[1], probe_settings, PROBE_SETTINGS_MAX_SIZE);
			response_len = PROBE_SETTINGS_MAX_SIZE + 1;
		} else {
			response[1] = -1;
			response_len = 1;
		}
		break;

	case ID_DAP_VENDOR_WRITE_SETTINGS:
		temp = request[0];
		if (temp > PROBE_SETTINGS_MAX_SIZE) {
			ret = -DAP_VENDOR_ERR_INVALID_SIZE;
			response[1] = ret;
		} else {
			ret = write_internal_settings((const probe_settings_ut *)(request + 1),
						      (uint16_t)temp);
			response[1] = ret;
		}
		break;

	default:
		flash_led = false;
		LOG_WRN("Unknown vendor command: 0x%02X", cmd_id);
		/* Unknown vendor command */
		response[0] = ID_DAP_INVALID;
		response_len = 1;
		break;
	}

	if (flash_led) {
		led_send_action((led_action_t *)&LED_GREEN_FLASH);
	}

	return response_len;
}
```

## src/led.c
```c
/*
 * Copyright 2025 Ezurio
 *
 * SPDX-License-Identifier: LicenseRef-Ezurio-Clause
 */

#include <zephyr/logging/log.h>
LOG_MODULE_REGISTER(app_led, CONFIG_DVK_PROBE_LOG_LEVEL);

#include "led.h"

const struct device *const led_strip = DEVICE_DT_GET(DT_ALIAS(ledstrip0));
/* Current LED status */
static struct led_rgb led_status;
/* New LED status to be applied */
static struct led_rgb new_led_status;
static struct k_work led_update_work;
static struct k_spinlock led_status_lock;

ZBUS_CHAN_DEFINE(led_chan,                /* Name */
		 led_action_t,            /* Message type */
		 NULL,                    /* Validator */
		 NULL,                    /* User data */
		 ZBUS_OBSERVERS(led_sub), /* observers */
		 ZBUS_MSG_INIT(.dev = NULL, .color = LED_COLOR_OFF, .on_time_ms = 0,
			       .off_time_ms = 0, .repeat_count = 0) /* Initial value */
);

const led_action_t LED_BLUE_FLASH = {
	.dev = led_strip,
	.color = LED_COLOR_BLUE,
	.on_time_ms = LED_FLASH_FAST_TIME_MS,
	.off_time_ms = 0,
	.repeat_count = 0,
};

const led_action_t LED_RED_FLASH = {
	.dev = led_strip,
	.color = LED_COLOR_RED,
	.on_time_ms = LED_FLASH_FAST_TIME_MS,
	.off_time_ms = 0,
	.repeat_count = 0,
};

const led_action_t LED_GREEN_FLASH = {
	.dev = led_strip,
	.color = LED_COLOR_GREEN,
	.on_time_ms = LED_FLASH_FAST_TIME_MS,
	.off_time_ms = 0,
	.repeat_count = 0,
};

int led_send_action(led_action_t *action)
{
	int ret;

	if (action == NULL) {
		return -EINVAL;
	}

	ret = zbus_chan_pub(&led_chan, action, K_NO_WAIT);
	if (ret == 0) {
		LOG_DBG("Published LED Action: Color R:%d G:%d B:%d On:%d Off:%d Repeat:%d",
			action->color.r, action->color.g, action->color.b, action->on_time_ms,
			action->off_time_ms, action->repeat_count);
	}

	return ret;
}

static int set_led_color(const struct device *dev, struct led_rgb *led_color)
{
	int ret;
	k_spinlock_key_t key;

	ret = led_strip_update_rgb(dev, led_color, LED_STRIP_NUM_PIXELS);
	if (ret) {
		LOG_ERR("Failed to set LED color %d", ret);
		return ret;
	}

	key = k_spin_lock(&led_status_lock);
	memcpy(&led_status, led_color, sizeof(struct led_rgb));
	k_spin_unlock(&led_status_lock, key);

	return 0;
}

int led_do_action(led_action_t *action)
{
	int ret;
	int repeat = 0;
	struct led_rgb off_color = LED_COLOR_OFF;

	if (action == NULL) {
		return -EINVAL;
	}

	if (action->dev == NULL) {
		return -EINVAL;
	}

	LOG_DBG("Run LED Action: Color R:%d G:%d B:%d On:%d Off:%d Repeat:%d", action->color.r,
		action->color.g, action->color.b, action->on_time_ms, action->off_time_ms,
		action->repeat_count);

	do {
		/* Set LED to desired color */
		ret = set_led_color(action->dev, &action->color);
		if (ret) {
			LOG_ERR("Failed to set LED color %d", ret);
			return ret;
		}
		k_msleep(action->on_time_ms);

		/* Turn off LED */
		ret = set_led_color(action->dev, &off_color);
		if (ret) {
			LOG_ERR("Failed to turn off LED %d", ret);
			return ret;
		}
		k_msleep(action->off_time_ms);

		repeat++;
	} while (repeat < action->repeat_count);
	return 0;
}

static void led_update_work_handler(struct k_work *work)
{
	ARG_UNUSED(work);
	set_led_color(led_strip, &new_led_status);
}

void toggle_led(led_color_t led_color)
{
	k_spinlock_key_t key;

	key = k_spin_lock(&led_status_lock);
	switch (led_color) {
	case LED_RED:
		new_led_status.r = led_status.r ? 0 : (int)(255 * LED_LEVEL_LIMIT);
		break;
	case LED_GREEN:
		new_led_status.g = led_status.g ? 0 : (int)(255 * LED_LEVEL_LIMIT);
		break;
	case LED_BLUE:
		new_led_status.b = led_status.b ? 0 : (int)(255 * LED_LEVEL_LIMIT);
		break;
	default:
		return;
	}
	k_spin_unlock(&led_status_lock, key);
	k_work_submit(&led_update_work);
}

void led_off(led_color_t led_color)
{
	k_spinlock_key_t key;

	key = k_spin_lock(&led_status_lock);
	switch (led_color) {
	case LED_RED:
		new_led_status.r = 0;
		break;
	case LED_GREEN:
		new_led_status.g = 0;
		break;
	case LED_BLUE:
		new_led_status.b = 0;
		break;
	default:
		return;
	}
	k_spin_unlock(&led_status_lock, key);
	k_work_submit(&led_update_work);
}

int led_init(void)
{
	if (!device_is_ready(led_strip)) {
		LOG_ERR("LED strip device not ready");
		return -ENODEV;
	}

	k_work_init(&led_update_work, led_update_work_handler);

	/* Initialize LED strip to off */
	set_led_color(led_strip, &led_status);
	return 0;
}
```

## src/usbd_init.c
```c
/*
 * Copyright (c) 2023 Nordic Semiconductor ASA
 * Copyright 2025 Ezurio
 *
 * SPDX-License-Identifier: LicenseRef-Ezurio-Clause
 */

#include <stdint.h>

#include <zephyr/device.h>
#include <zephyr/usb/usbd.h>
#include <zephyr/usb/bos.h>
#include <zephyr/usb/msos_desc.h>
#include <cmsis_dap.h>

#include <zephyr/logging/log.h>
LOG_MODULE_REGISTER(dvk_probe_usbd_config, CONFIG_DVK_PROBE_LOG_LEVEL);

#include "msosv2.h"

/* doc device instantiation start */
/*
 * Instantiate a context named app_usbd using the default USB device
 * controller, the vendor ID, and the product ID.
 */
USBD_DEVICE_DEFINE(app_usbd, DEVICE_DT_GET(DT_NODELABEL(zephyr_udc0)), CONFIG_APP_USBD_VID,
		   CONFIG_APP_USBD_PID);
/* doc device instantiation end */

/* doc string instantiation start */
USBD_DESC_LANG_DEFINE(app_lang);
USBD_DESC_MANUFACTURER_DEFINE(app_mfr, CONFIG_APP_USBD_MANUFACTURER);
USBD_DESC_PRODUCT_DEFINE(app_product, CONFIG_APP_USBD_PRODUCT);
IF_ENABLED(CONFIG_HWINFO, (USBD_DESC_SERIAL_NUMBER_DEFINE(app_sn)));

/* doc string instantiation end */

USBD_DESC_CONFIG_DEFINE(fs_cfg_desc, "FS Configuration");

/* doc configuration instantiation start */
static const uint8_t attributes =
	(IS_ENABLED(CONFIG_APP_USBD_SELF_POWERED) ? USB_SCD_SELF_POWERED : 0) |
	(IS_ENABLED(CONFIG_APP_USBD_REMOTE_WAKEUP) ? USB_SCD_REMOTE_WAKEUP : 0);

USBD_CONFIGURATION_DEFINE(app_fs_config, attributes, CONFIG_APP_USBD_MAX_POWER, &fs_cfg_desc);
/* doc configuration instantiation end */

#if CONFIG_APP_USBD_20_EXTENSION_DESC
/*
 * This does not yet provide valuable information, but rather serves as an
 * example, and will be improved in the future.
 */
static const struct usb_bos_capability_lpm bos_cap_lpm = {
	.bLength = sizeof(struct usb_bos_capability_lpm),
	.bDescriptorType = USB_DESC_DEVICE_CAPABILITY,
	.bDevCapabilityType = USB_BOS_CAPABILITY_EXTENSION,
	.bmAttributes = 0UL,
};

USBD_DESC_BOS_DEFINE(app_usbext, sizeof(bos_cap_lpm), &bos_cap_lpm);
#endif

static void app_fix_code_triple(struct usbd_context *uds_ctx, const enum usbd_speed speed)
{
	/* Always use class code information from Interface Descriptors */
	if (IS_ENABLED(CONFIG_USBD_CDC_ACM_CLASS) || IS_ENABLED(CONFIG_USBD_CDC_ECM_CLASS) ||
	    IS_ENABLED(CONFIG_USBD_CDC_NCM_CLASS) || IS_ENABLED(CONFIG_USBD_MIDI2_CLASS) ||
	    IS_ENABLED(CONFIG_USBD_AUDIO2_CLASS) || IS_ENABLED(CONFIG_USBD_VIDEO_CLASS)) {
		/*
		 * Class with multiple interfaces have an Interface
		 * Association Descriptor available, use an appropriate triple
		 * to indicate it.
		 */
		usbd_device_set_code_triple(uds_ctx, speed, USB_BCC_MISCELLANEOUS, 0x02, 0x01);
	} else {
		usbd_device_set_code_triple(uds_ctx, speed, 0, 0, 0);
	}
}

struct usbd_context *app_usbd_setup_device(usbd_msg_cb_t msg_cb)
{
	int err;

	/* doc add string descriptor start */
	err = usbd_add_descriptor(&app_usbd, &app_lang);
	if (err) {
		LOG_ERR("Failed to initialize language descriptor (%d)", err);
		return NULL;
	}

	err = usbd_add_descriptor(&app_usbd, &app_mfr);
	if (err) {
		LOG_ERR("Failed to initialize manufacturer descriptor (%d)", err);
		return NULL;
	}

	err = usbd_add_descriptor(&app_usbd, &app_product);
	if (err) {
		LOG_ERR("Failed to initialize product descriptor (%d)", err);
		return NULL;
	}

	IF_ENABLED(CONFIG_HWINFO, (
		err = usbd_add_descriptor(&app_usbd, &app_sn);
	))
	if (err) {
		LOG_ERR("Failed to initialize SN descriptor (%d)", err);
		return NULL;
	}
	/* doc add string descriptor end */

	/* doc configuration register start */
	err = usbd_add_configuration(&app_usbd, USBD_SPEED_FS, &app_fs_config);
	if (err) {
		LOG_ERR("Failed to add Full-Speed configuration");
		return NULL;
	}
	/* doc configuration register end */

	/* Register the USB classes in the order we want them to appear */
	err = usbd_register_class(&app_usbd, "dap_func_0", USBD_SPEED_FS, 1);
	if (err) {
		LOG_ERR("Failed to register dap_func_0 FS (%d)", err);
		return NULL;
	}
	err = usbd_register_class(&app_usbd, "cdc_acm_0", USBD_SPEED_FS, 1);
	if (err) {
		LOG_ERR("Failed to register cdc_acm_0 FS (%d)", err);
		return NULL;
	}
	err = usbd_register_class(&app_usbd, "cdc_acm_1", USBD_SPEED_FS, 1);
	if (err) {
		LOG_ERR("Failed to register cdc_acm_1 FS (%d)", err);
		return NULL;
	}
#if DT_NODE_EXISTS(DT_NODELABEL(cdc_acm_uart2))
	err = usbd_register_class(&app_usbd, "cdc_acm_2", USBD_SPEED_FS, 1);
	if (err) {
		LOG_ERR("Failed to register cdc_acm_2 FS (%d)", err);
		return NULL;
	}
#endif

	app_fix_code_triple(&app_usbd, USBD_SPEED_FS);
	usbd_self_powered(&app_usbd, attributes & USB_SCD_SELF_POWERED);

	if (msg_cb != NULL) {
		/* doc device init-and-msg start */
		err = usbd_msg_register_cb(&app_usbd, msg_cb);
		if (err) {
			LOG_ERR("Failed to register message callback");
			return NULL;
		}
		/* doc device init-and-msg end */
	}

	/* Set USB version to 2.01 to enable BOS descriptor support */
	(void)usbd_device_set_bcd_usb(&app_usbd, USBD_SPEED_FS, 0x0201);

#if CONFIG_APP_USBD_20_EXTENSION_DESC
	err = usbd_add_descriptor(&app_usbd, &app_usbext);
	if (err) {
		LOG_ERR("Failed to add USB 2.0 Extension Descriptor");
		return NULL;
	}
#endif

	err = usbd_add_descriptor(&app_usbd, &bos_vreq_msosv2);
	if (err) {
		LOG_ERR("Failed to add MSOSv2 capability descriptor");
		return NULL;
	}

	return &app_usbd;
}

struct usbd_context *app_usbd_init_device(usbd_msg_cb_t msg_cb)
{
	int err;

	if (app_usbd_setup_device(msg_cb) == NULL) {
		return NULL;
	}

	/* doc device init start */
	err = usbd_init(&app_usbd);
	if (err) {
		LOG_ERR("Failed to initialize device support");
		return NULL;
	}
	/* doc device init end */

	return &app_usbd;
}
```
